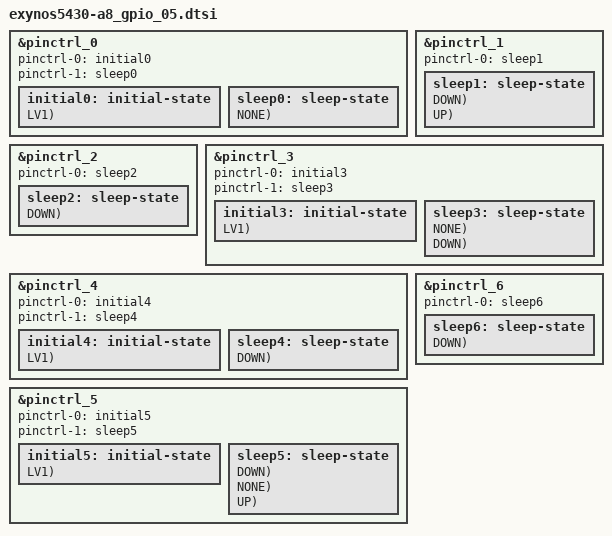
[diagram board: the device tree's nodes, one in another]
/*
 * SAMSUNG UNIVERSAL5430 board device tree source
 *
 * Copyright (c) 2014 Samsung Electronics Co., Ltd.
 *		http://www.samsung.com
 *
 * This program is free software; you can redistribute it and/or modify
 * it under the terms of the GNU General Public License version 2 as
 * published by the Free Software Foundation.
*/

#include "exynos_gpio_config_macros.dtsi"

/* A8 Project Rev05 Support */

&pinctrl_0 {
	pinctrl-names = "default","sleep";
	pinctrl-0 = <&initial0>;
	pinctrl-1 = <&sleep0>;
	initial0: initial-state {
		PIN_IN(gpa3-7, NONE, LV1);  /* IF_PMIC_RST */
	};
	sleep0: sleep-state {
		PIN_SLP(gpa3-7, OUT1, NONE);	/* IF_PMIC_RST */
	};
};

&pinctrl_1 {
	pinctrl-names = "sleep";
	pinctrl-0 = <&sleep1>;
	sleep1: sleep-state {
		PIN_SLP(gpz0-0, INPUT, DOWN);	/* MM_I2S_CLK */
		PIN_SLP(gpz0-1, INPUT, DOWN);	/* NC */
		PIN_SLP(gpz0-2, INPUT, DOWN);	/* MM_I2S_SYNC */
		PIN_SLP(gpz0-3, INPUT, DOWN);	/* MM_I2S_DI */
		PIN_SLP(gpz0-4, INPUT, DOWN);	/* MM_I2S_DO */
		PIN_SLP(gpz0-5, INPUT, DOWN);	/* NC */
		PIN_SLP(gpz0-6, INPUT, DOWN);	/* NC */

		PIN_SLP(gpz1-0, OUT1, UP);	/* BT_UART_TXD */
		PIN_SLP(gpz1-1, INPUT, UP);	/* BT_UART_RXD */
		PIN_SLP(gpz1-2, INPUT, UP);	/* BT_UART_CTS */
		PIN_SLP(gpz1-3, OUT1, UP);	/* BT_UART_RTS */
	};
};

&pinctrl_2 {
	pinctrl-names = "sleep";
	pinctrl-0 = <&sleep2>;
	sleep2: sleep-state {
		PIN_SLP(gpv6-0, INPUT, DOWN);	/* NC */
		PIN_SLP(gpv6-1, INPUT, DOWN);	/* NC */
		PIN_SLP(gpv6-2, INPUT, DOWN);	/* NC */
	};
};

&pinctrl_3 {
	pinctrl-names = "default","sleep";
	pinctrl-0 = <&initial3>;
	pinctrl-1 = <&sleep3>;
	initial3: initial-state {
		PIN_IN(gph1-0, NONE, LV1);	/* 10K PU */
		PIN_IN(gph1-1, DOWN, LV1);	/* NC */
		PIN_IN(gph1-2, NONE, LV1);	/* 10K PU */
		PIN_IN(gph1-3, DOWN, LV1);	/* NC */

		PIN_IN(gpr4-2, DOWN, LV1);	/* NC */

		PIN_IN(gpr0-3, DOWN, LV1);	/* NC */
		PIN_IN(gpr0-4, DOWN, LV1);	/* NC */

		PIN_IN(gpr3-4, DOWN, LV1);	/* NC */
		PIN_IN(gpr3-5, DOWN, LV1);	/* NC */
		PIN_IN(gpr3-6, DOWN, LV1);	/* NC */
		PIN_IN(gpr3-7, DOWN, LV1);	/* NC */
	};
	sleep3: sleep-state {
		PIN_SLP(gph1-0, INPUT, NONE);	/* 10K PU */
		PIN_SLP(gph1-1, INPUT, DOWN);	/* NC */
		PIN_SLP(gph1-2, INPUT, NONE);	/* 10K PU */
		PIN_SLP(gph1-3, INPUT, DOWN);	/* NC */

		PIN_SLP(gpr4-0, INPUT, DOWN);	/* T_FLASH_CLK */
		PIN_SLP(gpr4-1, INPUT, NONE);	/* T_FLASH_CMD */
		PIN_SLP(gpr4-2, INPUT, DOWN);	/* NC */
		PIN_SLP(gpr4-3, INPUT, NONE);	/* T_FLASH_D0 */
		PIN_SLP(gpr4-4, INPUT, NONE);	/* T_FLASH_D1 */
		PIN_SLP(gpr4-5, INPUT, NONE);	/* T_FLASH_D2 */
		PIN_SLP(gpr4-6, INPUT, NONE);	/* T_FLASH_D3 */

		PIN_SLP(gpr0-0, INPUT, DOWN);	/* TP_NAND_CLK */
		PIN_SLP(gpr0-1, INPUT, NONE);	/* 10K PU */
		PIN_SLP(gpr0-2, INPUT, DOWN);	/* 10K PD */
		PIN_SLP(gpr0-3, INPUT, DOWN);	/* NC */
		PIN_SLP(gpr0-4, INPUT, DOWN);	/* NC */

		PIN_SLP(gpr1-0, INPUT, NONE);	/* 51K PU */
		PIN_SLP(gpr1-1, INPUT, NONE);	/* 51K PU */
		PIN_SLP(gpr1-2, INPUT, NONE);	/* 51K PU */
		PIN_SLP(gpr1-3, INPUT, NONE);	/* 51K PU */
		PIN_SLP(gpr1-4, INPUT, NONE);	/* 51K PU */
		PIN_SLP(gpr1-5, INPUT, NONE);	/* 51K PU */
		PIN_SLP(gpr1-6, INPUT, NONE);	/* 51K PU */
		PIN_SLP(gpr1-7, INPUT, NONE);	/* 51K PU */

		PIN_SLP(gpr2-0, OUT0, DOWN);	/* WLAN_SDIO_CLK */
		PIN_SLP(gpr2-1, INPUT, NONE);	/* WLAN_SDIO_CMD */

		PIN_SLP(gpr3-0, INPUT, NONE);	/* WLAN_SDIO_D(0) */
		PIN_SLP(gpr3-1, INPUT, NONE);	/* WLAN_SDIO_D(1) */
		PIN_SLP(gpr3-2, INPUT, NONE);	/* WLAN_SDIO_D(2) */
		PIN_SLP(gpr3-3, INPUT, NONE);	/* WLAN_SDIO_D(3) */
		PIN_SLP(gpr3-4, INPUT, DOWN);	/* NC */
		PIN_SLP(gpr3-5, INPUT, DOWN);	/* NC */
		PIN_SLP(gpr3-6, INPUT, DOWN);	/* NC */
		PIN_SLP(gpr3-7, INPUT, DOWN);	/* NC */
	};
};

&pinctrl_4 {
	pinctrl-names = "default","sleep";
	pinctrl-0 = <&initial4>;
	pinctrl-1 = <&sleep4>;
	initial4: initial-state {
		PIN_IN(gpj0-0, DOWN, LV1);	/* NC */
		PIN_IN(gpj0-1, DOWN, LV1);	/* NC */
		PIN_IN(gpj0-2, DOWN, LV1);	/* NC */
	};
	sleep4: sleep-state {
		PIN_SLP(gpj0-0, INPUT, DOWN);	/* NC */
		PIN_SLP(gpj0-1, INPUT, DOWN);	/* NC */
		PIN_SLP(gpj0-2, INPUT, DOWN);	/* NC */
	};
};

&pinctrl_5 {
	pinctrl-names = "default","sleep";
	pinctrl-0 = <&initial5>;
	pinctrl-1 = <&sleep5>;
	initial5: initial-state {
		//PIN_OUT_SET(gpv7-0, 0, LV1);	/* UART_SW_CTL */


		PIN_IN(gpc3-0, DOWN, LV1);	/* NC */
		PIN_IN(gpc3-1, DOWN, LV1);	/* NC */
		PIN_IN(gpc3-2, DOWN, LV1);	/* NC */
		PIN_IN(gpc3-3, DOWN, LV1);	/* NC */

		PIN_IN(gpd1-2, DOWN, LV1);	/* NC */
		PIN_IN(gpd1-3, DOWN, LV1);	/* NC */

		PIN_IN(gpd2-5, DOWN, LV1);	/* NC */

		PIN_IN(gpd4-3, NONE, LV1);	/* SENSOR_I2C_SDA */
		PIN_IN(gpd4-4, NONE, LV1);	/* SENSOR_I2C_SCL */

		PIN_IN(gpd8-0, DOWN, LV1);	/* NC */

		PIN_IN(gpd6-0, DOWN, LV1);	/* NC */
		PIN_IN(gpd6-1, DOWN, LV1);	/* NC */
		PIN_IN(gpd6-2, DOWN, LV1);	/* NC */
		PIN_IN(gpd6-3, DOWN, LV1);	/* NC */
		PIN_IN(gpd6-4, DOWN, LV1);	/* NC */
		PIN_IN(gpd6-5, DOWN, LV1);	/* NC */

		PIN_IN(gpf0-0, DOWN, LV1);	/* NC */
		PIN_IN(gpf0-1, DOWN, LV1);	/* NC */
		PIN_IN(gpf0-2, DOWN, LV1);	/* NC */
		PIN_IN(gpf0-3, DOWN, LV1);	/* NC */
		PIN_IN(gpf0-4, DOWN, LV1);	/* NC */
		PIN_IN(gpf0-5, DOWN, LV1);	/* NC */
		PIN_IN(gpf0-6, DOWN, LV1);	/* NC */
		PIN_IN(gpf0-7, DOWN, LV1);	/* CCI_MODE(NC) */
		PIN_IN(gpf4-1, NONE, LV1);	/* SENSOR_I2C_SCL acc */
		PIN_IN(gpf4-2, NONE, LV1);	/* SENSOR_I2C_SDA acc */
		PIN_IN(gpf5-0, NONE, LV1);	/* 10K Pull Up */
		PIN_IN(gpf5-5, DOWN, LV1);	/* GRIP_INT */

		PIN_IN(gpg3-7, DOWN, LV1);	/* NC */
	};
	sleep5: sleep-state {
		PIN_SLP(gpv7-0, PREV, DOWN);	/* UART_SW_CTL */
		PIN_SLP(gpv7-1, INPUT, DOWN);	/* PCD_INT */
		PIN_SLP(gpv7-2, PREV, NONE);	/* MLCD_RST */
		PIN_SLP(gpv7-3, PREV, NONE);	/* EAR_MIC_BIAS_LDO_EN */
		PIN_SLP(gpv7-4, INPUT, DOWN);	/* TDMB_INT */

		PIN_SLP(gpb0-0, INPUT, NONE);	/* FUEL_SDA_1.8V */
		PIN_SLP(gpb0-1, INPUT, NONE);	/* FUEL_SCL_1.8V */
		PIN_SLP(gpb0-2, INPUT, NONE);	/* TOUCH_I2C_SDA */
		PIN_SLP(gpb0-3, INPUT, NONE);	/* TOUCH_I2C_SCL */
		PIN_SLP(gpb0-4, INPUT, DOWN);	/* ERR_FG */

		//PIN_SLP(gpa0-6, INPUT, DOWN);	/* ELON1_EN */


		PIN_SLP(gpc0-1, INPUT, DOWN);	/* FLASH_LED_STROBE */
		PIN_SLP(gpc0-2, PREV, NONE);	/* FLASH_LED_TORCH */
		PIN_SLP(gpc0-3, INPUT, DOWN);	/* VT_CAM_NRST */
		PIN_SLP(gpc0-4, INPUT, DOWN);	/* MAIN_CAM_RST */
		PIN_SLP(gpc0-5, INPUT, DOWN);	/* MAIN_CAM_A2.95V_EN */
		PIN_SLP(gpc0-6, INPUT, DOWN);	/* NC */

		PIN_SLP(gpc1-0, INPUT, DOWN);	/* NC */
		PIN_SLP(gpc1-1, INPUT, DOWN);	/* NC */

		PIN_SLP(gpc2-0, INPUT, DOWN);	/* MAIN_CAM_SDA */
		PIN_SLP(gpc2-1, INPUT, DOWN);	/* MAIN_CAM_SCL */
		PIN_SLP(gpc2-2, INPUT, DOWN);	/* CAM_EEP_SCL_1P8 */
		PIN_SLP(gpc2-3, INPUT, DOWN);	/* CAM_EEP_SDA_1P8 */
		PIN_SLP(gpc2-4, INPUT, DOWN);	/* VT_CAM_SDA */
		PIN_SLP(gpc2-5, INPUT, DOWN);	/* VT_CAM_SCL */

		PIN_SLP(gpc3-0, INPUT, DOWN);	/* TDMB_SPI_CLK */
		PIN_SLP(gpc3-1, INPUT, DOWN);	/* TDMB_SPI_CS_N */
		PIN_SLP(gpc3-2, INPUT, DOWN);	/* TDMB_SPI_MISO */
		PIN_SLP(gpc3-3, INPUT, DOWN);	/* TDMB_SPI_MOSI */
		PIN_SLP(gpc3-4, INPUT, DOWN);	/* CP_SPI_CLK */
		PIN_SLP(gpc3-5, OUT1, NONE);	/* CP_SPI_CSN */
		PIN_SLP(gpc3-6, INPUT, DOWN);	/* CP_SPI_TXD */
		PIN_SLP(gpc3-7, INPUT, DOWN);	/* CP_SPI_RXD */

		PIN_SLP(gpg0-0, INPUT, DOWN);	/* NC */
		PIN_SLP(gpg0-1, INPUT, DOWN);	/* LCD_TE */

		PIN_SLP(gpd0-0, INPUT, UP);		/* GPS_UART_RXD */
		PIN_SLP(gpd0-1, INPUT, UP);		/* GPS_UART_TXD */
		PIN_SLP(gpd0-2, INPUT, DOWN);	/* GPS_UART_CTS */
		PIN_SLP(gpd0-3, OUT1, NONE);	/* GPS_UART_RTS */

		PIN_SLP(gpg3-0, INPUT, NONE);	/* CAM_EEP_SDA_1P8 */
		PIN_SLP(gpg3-1, INPUT, NONE);	/* CAM_EEP_SCL_1P8 */

		PIN_SLP(gpd1-0, INPUT, DOWN);	/* AP_RXD */
		PIN_SLP(gpd1-1, INPUT, DOWN);	/* AP_TXD */
		PIN_SLP(gpd1-2, INPUT, DOWN);	/* NC */
		PIN_SLP(gpd1-3, INPUT, DOWN);	/* NC */
		PIN_SLP(gpd1-4, INPUT, DOWN);	/* NC */
		PIN_SLP(gpd1-5, INPUT, DOWN);	/* NC */

		PIN_SLP(gpd2-0, INPUT, NONE);	/* AP_PMIC_SDA */
		PIN_SLP(gpd2-1, INPUT, NONE);	/* AP_PMIC_SCL */
		PIN_SLP(gpd2-2, INPUT, NONE);	/* IF_PMIC_SDA_1.8V */
		PIN_SLP(gpd2-3, INPUT, NONE);	/* IF_PMIC_SCL_1.8V */
		PIN_SLP(gpd2-4, OUT0, DOWN);	/* MOTOR_PWM */
		PIN_SLP(gpd2-5, INPUT, DOWN);	/* NC */
		PIN_SLP(gpd2-6, INPUT, NONE);	/* CODEC_SCL_1.8V */
		PIN_SLP(gpd2-7, INPUT, NONE);	/* CODEC_SDA_1.8V */

		PIN_SLP(gpd4-0, PREV, NONE);	/* MOTOR_EN */
		PIN_SLP(gpd4-1, PREV, DOWN);	/* BTP_OCP_EN  */
		PIN_SLP(gpd4-2, INPUT, DOWN);	/* NC */
		PIN_SLP(gpd4-3, INPUT, NONE);	/* SENSOR_I2C_SDA */
		PIN_SLP(gpd4-4, INPUT, NONE);	/* SENSOR_I2C_SCL */

		PIN_SLP(gpd5-0, OUT0, DOWN);	/* BTP_SPI_CLK */
		PIN_SLP(gpd5-1, OUT0, DOWN);	/* BTP_SPI_CS_N */
		PIN_SLP(gpd5-2, INPUT, DOWN);	/* BTP_SPI_MISO */
		PIN_SLP(gpd5-3, OUT0, DOWN);	/* BTP_SPI_MOSI */

		PIN_SLP(gpd8-0, INPUT, DOWN);	/* NC */
		PIN_SLP(gpd8-1, INPUT, DOWN);	/* NC */

		PIN_SLP(gpd6-0, INPUT, DOWN);	/* NC */
		PIN_SLP(gpd6-1, INPUT, DOWN);	/* NC */
		PIN_SLP(gpd6-2, INPUT, DOWN);	/* NC */
		PIN_SLP(gpd6-3, INPUT, DOWN);	/* NC */
		PIN_SLP(gpd6-4, INPUT, DOWN);	/* NC */
		PIN_SLP(gpd6-5, INPUT, DOWN);	/* NC */

		PIN_SLP(gpd7-0, OUT0, DOWN);	/* MAIN_CAM_MCLK */
		PIN_SLP(gpd7-1, INPUT, DOWN);	/* NFC_MCLK */
		PIN_SLP(gpd7-2, OUT0, DOWN);	/* VT_CAM_MCLK */

		PIN_SLP(gpf0-0, INPUT, DOWN);	/* NC */
		PIN_SLP(gpf0-1, INPUT, DOWN);	/* NC */
		PIN_SLP(gpf0-2, INPUT, DOWN);	/* NC */
		PIN_SLP(gpf0-3, INPUT, DOWN);	/* NC */
		PIN_SLP(gpf0-4, INPUT, DOWN);	/* NC */
		PIN_SLP(gpf0-5, INPUT, DOWN);   /* NC */
		PIN_SLP(gpf0-6, INPUT, DOWN);	/* NC */
		PIN_SLP(gpf0-7, INPUT, DOWN);	/* CCI_MODE(NC) */

		PIN_SLP(gpf1-0, INPUT, NONE);	/* MUIC_SCL_1.8V */
		PIN_SLP(gpf1-1, INPUT, NONE);	/* MUIC_SDA_1.8V */
		PIN_SLP(gpf1-2, PREV, NONE);	/* CP_PMIC_PWR_HOLD */
		PIN_SLP(gpf1-3, INPUT, DOWN);	/* LCD_TE */
		PIN_SLP(gpf1-4, INPUT, DOWN);	/* NC */
		PIN_SLP(gpf1-5, PREV, NONE);	/* LCD_1.6V_EN */
		PIN_SLP(gpf1-6, PREV, NONE);	/* CHG_EN */
		PIN_SLP(gpf1-7, INPUT, DOWN);	/* NC */

		PIN_SLP(gpf2-0, INPUT, DOWN);	/* NC */
		PIN_SLP(gpf2-1, INPUT, DOWN);	/* NC */
		PIN_SLP(gpf2-2, INPUT, DOWN);	/* FPS_CHECK */
		PIN_SLP(gpf2-3, INPUT, DOWN);	/* NC */

		PIN_SLP(gpf3-0, PREV, NONE);	/* CODEC_RESET_N */
		PIN_SLP(gpf3-1, INPUT, DOWN);	/* MST_D_N */
		PIN_SLP(gpf3-2, INPUT, DOWN);	/* NC */
		PIN_SLP(gpf3-3, INPUT, DOWN);	/* AMP_RST */
		PIN_SLP(gpf3-4, PREV, NONE);	/* LDO17_EN */
		PIN_SLP(gpf3-5, PREV, NONE);	/* BOOT_LDO */

		PIN_SLP(gpf4-0, OUT0, DOWN);	/* BTP_LDO_EN */
		PIN_SLP(gpf4-1, INPUT, NONE);	/* SENSOR_I2C_SCL acc */
		PIN_SLP(gpf4-2, INPUT, NONE);	/*  SENSOR_I2C_SDA acc */
		PIN_SLP(gpf4-3, INPUT, DOWN);	/* AP2CP_STATUS */
		PIN_SLP(gpf4-4, INPUT, DOWN);	/* AP2CP_DUMP_NOTI_n */
		PIN_SLP(gpf4-5, INPUT, DOWN);	/* NC */
		PIN_SLP(gpf4-6, INPUT, DOWN);	/* AP2CP_WAKEUP */
		PIN_SLP(gpf4-7, INPUT, DOWN);	/* AP2CP_GPIO_RSV */

		PIN_SLP(gpf5-0, INPUT, NONE);	/* 10K Pull Up */
		PIN_SLP(gpf5-1, INPUT, DOWN);	/* NC */
		PIN_SLP(gpf5-2, OUT0, NONE);	/* BTP_RST_N */
		PIN_SLP(gpf5-3, INPUT, DOWN);	/* NC */
		PIN_SLP(gpf5-4, OUT1, NONE);	/* WRSTB_IN */
		PIN_SLP(gpf5-5, INPUT, DOWN);	/* GRIP_INT */
		PIN_SLP(gpf5-6, INPUT, DOWN);	/* NC */
		PIN_SLP(gpf5-7, INPUT, DOWN);	/* NC */

		PIN_SLP(gpg1-0, INPUT, DOWN);	/* NC */
		PIN_SLP(gpg1-1, INPUT, DOWN);	/* NC */
		PIN_SLP(gpg1-2, INPUT, DOWN);	/* NC */
		PIN_SLP(gpg1-3, INPUT, DOWN);	/* NC */
		PIN_SLP(gpg1-4, PREV, DOWN);	/* BT_EN */

		PIN_SLP(gpg2-0, PREV, NONE);	/* WLAN_EN */
		PIN_SLP(gpg2-1, OUT0, DOWN);	/* GPS_EN */
		PIN_SLP(gpg2-2, INPUT, DOWN);	/* FACTORY_DISCHAG */
		PIN_SLP(gpg2-3, PREV, NONE);	/* CP_PMIC_PWR_EN */
		PIN_SLP(gpg2-4, OUT0, NONE);	/* PDA_ACTIVE */

		PIN_SLP(gpc0-0, INPUT, NONE);	/* MEM_LDO_SDA */
		PIN_SLP(gpc0-7, INPUT, NONE);	/* MEM_LDO_SCL */
		PIN_SLP(gpg3-2, INPUT, NONE);	/* SPK_AMP_SDA */
		PIN_SLP(gpg3-3, INPUT, NONE);	/* SPK_AMP_SCL */
		PIN_SLP(gpg3-4, INPUT, NONE);	/* HW_REV0 */
		PIN_SLP(gpg3-5, INPUT, NONE);	/* HW_REV1 */
		PIN_SLP(gpg3-6, INPUT, NONE);	/* HW_REV2 */
		PIN_SLP(gpg3-7, INPUT, DOWN);	/* NC */
	};
};

&pinctrl_6 {
	pinctrl-names = "sleep";
	pinctrl-0 = <&sleep6>;
	sleep6: sleep-state {
		PIN_SLP(gpj1-0, INPUT, DOWN);	/* TS_I2C_SDA */
		PIN_SLP(gpj1-1, INPUT, DOWN);	/* TS_I2C_SCL */
		PIN_SLP(gpj1-2, INPUT, DOWN);	/* NC */
	};
};
